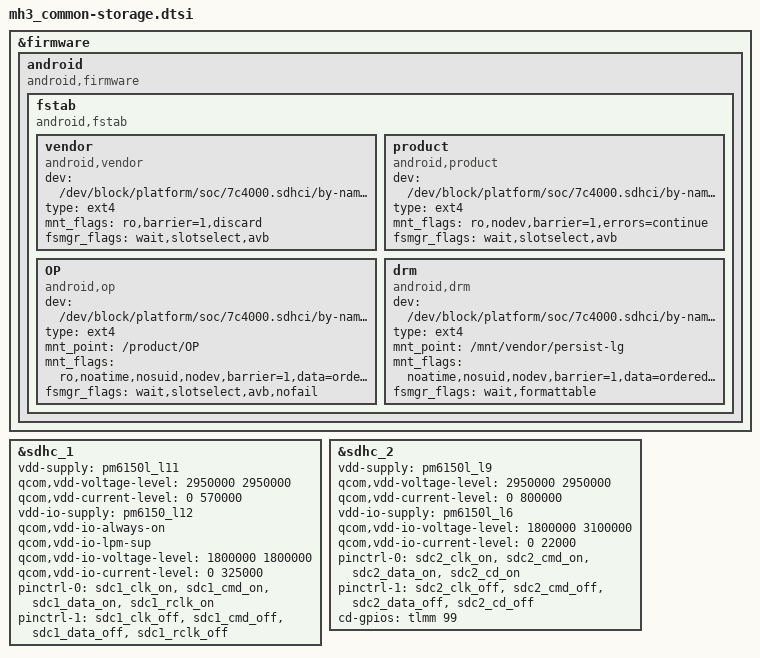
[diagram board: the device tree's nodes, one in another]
/*
 * Copyright (c) 2018, The Linux Foundation. All rights reserved.
 *
 * This program is free software; you can redistribute it and/or modify
 * it under the terms of the GNU General Public License version 2 and
 * only version 2 as published by the Free Software Foundation.
 *
 * This program is distributed in the hope that it will be useful,
 * but WITHOUT ANY WARRANTY; without even the implied warranty of
 * MERCHANTABILITY or FITNESS FOR A PARTICULAR PURPOSE.  See the
 * GNU General Public License for more details.
 */

&firmware {
	android {
		compatible = "android,firmware";
		fstab {
			compatible = "android,fstab";
			vendor {
				compatible = "android,vendor";
				dev = "/dev/block/platform/soc/7c4000.sdhci/by-name/vendor";
				type = "ext4";
				mnt_flags = "ro,barrier=1,discard";
				fsmgr_flags = "wait,slotselect,avb";
				status = "ok";
			};
			product {
				compatible = "android,product";
				dev = "/dev/block/platform/soc/7c4000.sdhci/by-name/product";
				type = "ext4";
				mnt_flags = "ro,nodev,barrier=1,errors=continue";
				fsmgr_flags = "wait,slotselect,avb";
				status = "ok";
			};
			OP {
				compatible = "android,op";
				dev = "/dev/block/platform/soc/7c4000.sdhci/by-name/OP";
				type = "ext4";
				mnt_point = "/product/OP";
				mnt_flags = "ro,noatime,nosuid,nodev,barrier=1,data=ordered,noauto_da_alloc";
				fsmgr_flags = "wait,slotselect,avb,nofail";
				status = "ok";
			};
			drm {
				compatible = "android,drm";
				dev = "/dev/block/platform/soc/7c4000.sdhci/by-name/drm";
				type = "ext4";
				mnt_point = "/mnt/vendor/persist-lg";
				mnt_flags = "noatime,nosuid,nodev,barrier=1,data=ordered,noauto_da_alloc,errors=continue";
				fsmgr_flags = "wait,formattable";
				status = "ok";
			};
		};
	};
};

&sdhc_1 {
	vdd-supply = <&pm6150l_l11>;
	qcom,vdd-voltage-level = <2950000 2950000>;
	qcom,vdd-current-level = <0 570000>;

	vdd-io-supply = <&pm6150_l12>;
	qcom,vdd-io-always-on;
	qcom,vdd-io-lpm-sup;
	qcom,vdd-io-voltage-level = <1800000 1800000>;
	qcom,vdd-io-current-level = <0 325000>;

	pinctrl-names = "active", "sleep";
	pinctrl-0 = <&sdc1_clk_on &sdc1_cmd_on &sdc1_data_on &sdc1_rclk_on>;
	pinctrl-1 = <&sdc1_clk_off &sdc1_cmd_off &sdc1_data_off &sdc1_rclk_off>;

	status = "ok";
};

&sdhc_2 {
	vdd-supply = <&pm6150l_l9>;
	qcom,vdd-voltage-level = <2950000 2950000>;
	qcom,vdd-current-level = <0 800000>;

	vdd-io-supply = <&pm6150l_l6>;
	qcom,vdd-io-voltage-level = <1800000 3100000>;
	qcom,vdd-io-current-level = <0 22000>;

	pinctrl-names = "active", "sleep";
	pinctrl-0 = <&sdc2_clk_on  &sdc2_cmd_on &sdc2_data_on &sdc2_cd_on>;
	pinctrl-1 = <&sdc2_clk_off &sdc2_cmd_off &sdc2_data_off &sdc2_cd_off>;

	cd-gpios = <&tlmm 99 GPIO_ACTIVE_HIGH>;

	status = "ok";
};
